# STM32F407 register map
File version: 1.4
CPU: CM4 r0p1, little endian, MPU, FPU, 4 interrupt priority bits
Registers are 32-bit, read-write, reset 0x0 unless marked. A register's access mark holds for its fields unless they carry their own. Offsets are from the block's base; [hi:lo] are bit positions; {n}, {i} and the like mark numbered series.

## SYSCFG — System configuration controller
Base 0x40013800
0x00 MEMRM — memory remap register
  [1:0] MEM_MODE
0x04 PMC — peripheral mode configuration register
  [23] MII_RMII_SEL — Ethernet PHY interface selection
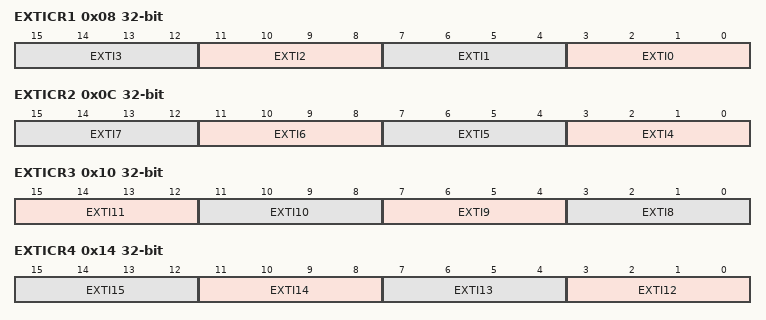
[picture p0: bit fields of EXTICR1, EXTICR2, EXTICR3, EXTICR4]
0x08 EXTICR1 — external interrupt configuration register 1
  [4n+3:4n] EXTI{n} (n=0..3) — EXTI x configuration (x = 0 to 3)
0x0C EXTICR2 — external interrupt configuration register 2
  [4n-13:4n-16] EXTI{n} (n=4..7) — EXTI x configuration (x = 4 to 7)
0x10 EXTICR3 — external interrupt configuration register 3
  [15:12] EXTI11 — EXTI x configuration (x = 8 to 11)
  [11:8] EXTI10
  [7:4] EXTI9 — EXTI x configuration (x = 8 to 11)
  [3:0] EXTI8 — EXTI x configuration (x = 8 to 11)
0x14 EXTICR4 — external interrupt configuration register 4
  [4n-45:4n-48] EXTI{n} (n=12..15) — EXTI x configuration (x = 12 to 15)
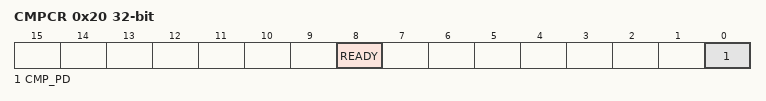
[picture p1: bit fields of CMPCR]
0x20 CMPCR ro — Compensation cell control register
  [8] READY
  [0] CMP_PD — Compensation cell power-down

## PWR — Power control
Base 0x40007000
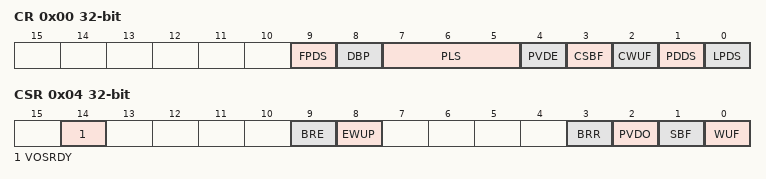
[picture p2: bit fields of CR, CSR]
0x00 CR — power control register
  [9] FPDS — Flash power down in Stop mode
  [8] DBP — Disable backup domain write protection
  [7:5] PLS — PVD level selection
  [4] PVDE — Power voltage detector enable
  [3] CSBF — Clear standby flag
  [2] CWUF — Clear wakeup flag
  [1] PDDS — Power down deepsleep
  [0] LPDS — Low-power deep sleep
0x04 CSR access per field — power control/status register
  [14] VOSRDY rw — Regulator voltage scaling output selection ready bit
  [9] BRE rw — Backup regulator enable
  [8] EWUP rw — Enable WKUP pin
  [3] BRR ro — Backup regulator ready
  [2] PVDO ro — PVD output
  [1] SBF ro — Standby flag
  [0] WUF ro — Wakeup flag

## IWDG — Independent watchdog
Base 0x40003000
0x00 KR wo — Key register
  [15:0] KEY — Key value (write only, read 0000h)
0x04 PR — Prescaler register
  [2:0] PR — Prescaler divider
0x08 RLR reset 0xFFF — Reload register
  [11:0] RL — Watchdog counter reload value
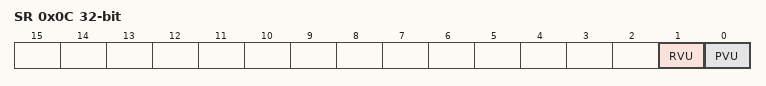
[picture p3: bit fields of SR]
0x0C SR ro — Status register
  [1] RVU — Watchdog counter reload value update
  [0] PVU — Watchdog prescaler value update

## WWDG — Window watchdog
Base 0x40002C00
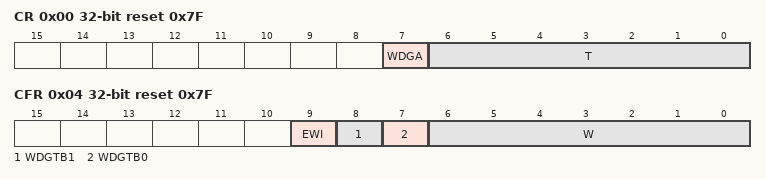
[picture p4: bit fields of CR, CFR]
0x00 CR reset 0x7F — Control register
  [7] WDGA — Activation bit
  [6:0] T — 7-bit counter (MSB to LSB)
0x04 CFR reset 0x7F — Configuration register
  [9] EWI — Early wakeup interrupt
  [8] WDGTB1 — Timer base
  [7] WDGTB0 — Timer base
  [6:0] W — 7-bit window value
0x08 SR — Status register
  [0] EWIF — Early wakeup interrupt flag

## C_ADC — Common ADC registers
Base 0x40012300
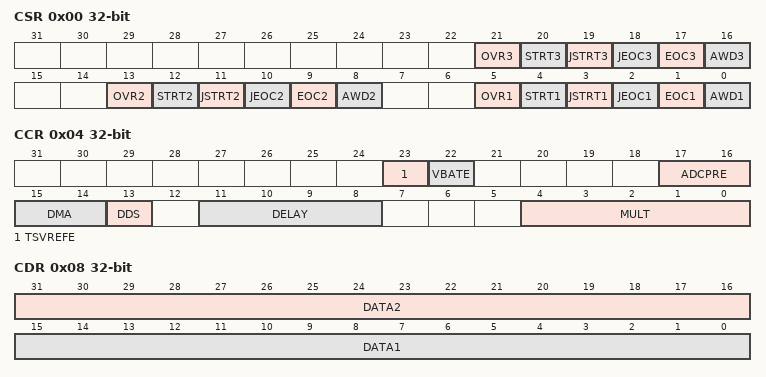
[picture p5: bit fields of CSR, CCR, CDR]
0x00 CSR ro — ADC Common status register
  [21] OVR3 — Overrun flag of ADC3
  [20] STRT3 — Regular channel Start flag of ADC 3
  [19] JSTRT3 — Injected channel Start flag of ADC 3
  [18] JEOC3 — Injected channel end of conversion of ADC 3
  [17] EOC3 — End of conversion of ADC 3
  [16] AWD3 — Analog watchdog flag of ADC 3
  [13] OVR2 — Overrun flag of ADC 2
  [12] STRT2 — Regular channel Start flag of ADC 2
  [11] JSTRT2 — Injected channel Start flag of ADC 2
  [10] JEOC2 — Injected channel end of conversion of ADC 2
  [9] EOC2 — End of conversion of ADC 2
  [8] AWD2 — Analog watchdog flag of ADC 2
  [5] OVR1 — Overrun flag of ADC 1
  [4] STRT1 — Regular channel Start flag of ADC 1
  [3] JSTRT1 — Injected channel Start flag of ADC 1
  [2] JEOC1 — Injected channel end of conversion of ADC 1
  [1] EOC1 — End of conversion of ADC 1
  [0] AWD1 — Analog watchdog flag of ADC 1
0x04 CCR — ADC common control register
  [23] TSVREFE — Temperature sensor and VREFINT enable
  [22] VBATE — VBAT enable
  [17:16] ADCPRE — ADC prescaler
  [15:14] DMA — Direct memory access mode for multi ADC mode
  [13] DDS — DMA disable selection for multi-ADC mode
  [11:8] DELAY — Delay between 2 sampling phases
  [4:0] MULT — Multi ADC mode selection
0x08 CDR ro — ADC common regular data register for dual and triple modes
  [31:16] DATA2 — 2nd data item of a pair of regular conversions
  [15:0] DATA1 — 1st data item of a pair of regular conversions
